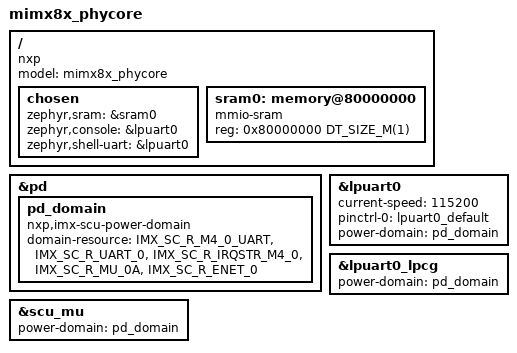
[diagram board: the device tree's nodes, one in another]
/*
 * Copyright (c) 2024
 *
 * SPDX-License-Identifier: Apache-2.0
 */

/dts-v1/;

#include <nxp/nxp_mimx8x_a35.dtsi>
#include "mimx8x_phycore-pinctrl.dtsi"
#include <zephyr/dt-bindings/ethernet/phy/ti-dp83867.h>

/ {
	model = "mimx8x_phycore";
	compatible = "nxp";

	chosen {
		zephyr,sram = &sram0;
		zephyr,console = &lpuart0;
		zephyr,shell-uart = &lpuart0;
	};

	sram0: memory@80000000 {
		device_type = "memory";
		compatible = "mmio-sram";
		reg = <0x80000000 DT_SIZE_M(1)>;
	};
};

&pd {
	pd_domain: pd_domain {
		compatible = "nxp,imx-scu-power-domain";
		domain-resource = <IMX_SC_R_M4_0_UART>, <IMX_SC_R_UART_0>,
		<IMX_SC_R_IRQSTR_M4_0>, <IMX_SC_R_MU_0A>, <IMX_SC_R_ENET_0>;
	};
};

&lpuart0 {
	status = "okay";
	current-speed = <115200>;
	pinctrl-0 = <&lpuart0_default>;
	pinctrl-names = "default";
	power-domain = <&pd_domain>;
};

&lpuart0_lpcg {
	status = "okay";
	power-domain = <&pd_domain>;
};

&scu_mu {
	status = "okay";
	power-domain = <&pd_domain>;
};
